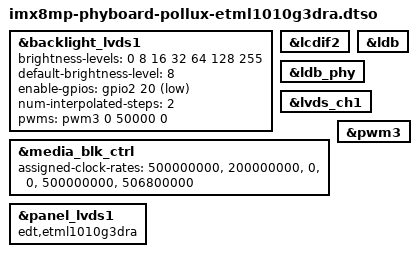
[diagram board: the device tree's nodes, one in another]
// SPDX-License-Identifier: (GPL-2.0-or-later OR MIT)
/*
 * Copyright (C) 2025 PHYTEC Messtechnik GmbH
 */

#include <dt-bindings/gpio/gpio.h>
#include <dt-bindings/clock/imx8mp-clock.h>

/dts-v1/;
/plugin/;

&backlight_lvds1 {
	brightness-levels = <0 8 16 32 64 128 255>;
	default-brightness-level = <8>;
	enable-gpios = <&gpio2 20 GPIO_ACTIVE_LOW>;
	num-interpolated-steps = <2>;
	pwms = <&pwm3 0 50000 0>;
	status = "okay";
};

&lcdif2 {
	status = "okay";
};

&ldb {
	status = "okay";
};

&ldb_phy {
	status = "okay";
};

&lvds_ch1 {
	status = "okay";
};

&media_blk_ctrl {
	/*
	 * The LVDS panel on this device uses 72.4 MHz pixel clock,
	 * set IMX8MP_VIDEO_PLL1 to 72.4 * 7 = 506.8 MHz so the LDB
	 * serializer and LCDIFv3 scanout engine can reach accurate
	 * pixel clock of exactly 72.4 MHz.
	 */
	assigned-clock-rates = <500000000>, <200000000>,
			       <0>, <0>, <500000000>,
			       <506800000>;
};

&panel_lvds1 {
	compatible = "edt,etml1010g3dra";
	status = "okay";
};

&pwm3 {
	status = "okay";
};
